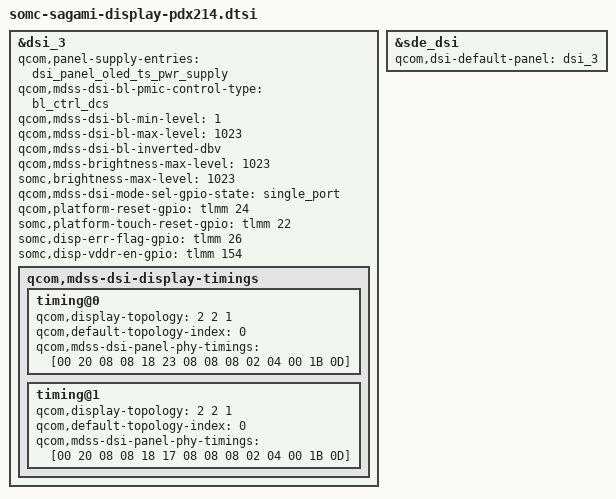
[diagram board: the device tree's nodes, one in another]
#include "dsi-panel-sofef03_m-amb609vp01-fhd_plus.dtsi"

&dsi_3 {
	qcom,panel-supply-entries = <&dsi_panel_oled_ts_pwr_supply>;
	qcom,mdss-dsi-bl-pmic-control-type = "bl_ctrl_dcs";
	qcom,mdss-dsi-bl-min-level = <1>;
	qcom,mdss-dsi-bl-max-level = <1023>;
	qcom,mdss-dsi-bl-inverted-dbv;
	qcom,mdss-brightness-max-level = <1023>;
	somc,brightness-max-level = <1023>;
	qcom,mdss-dsi-mode-sel-gpio-state = "single_port";

	qcom,platform-reset-gpio = <&tlmm 24 0>;
	somc,platform-touch-reset-gpio = <&tlmm 22 0>;
	somc,disp-err-flag-gpio = <&tlmm 26 0>;
	somc,disp-vddr-en-gpio = <&tlmm 154 0>;

	qcom,mdss-dsi-display-timings {
		timing@0 {
			qcom,display-topology = <2 2 1>;
			qcom,default-topology-index = <0>;
			qcom,mdss-dsi-panel-phy-timings = [00 20 08 08 18 23 08 08 08 02 04 00 1B 0D];
		};
		timing@1 {
			qcom,display-topology = <2 2 1>;
			qcom,default-topology-index = <0>;
			qcom,mdss-dsi-panel-phy-timings = [00 20 08 08 18 17 08 08 08 02 04 00 1B 0D];
		};
	};
};

&sde_dsi {
	qcom,dsi-default-panel = <&dsi_3>;
};
